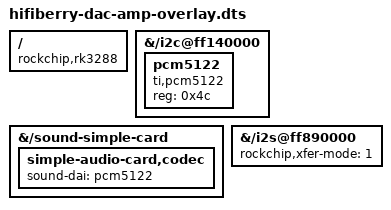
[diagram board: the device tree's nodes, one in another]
/dts-v1/;
/plugin/;

/ {
	compatible = "rockchip,rk3288";

	fragment@0 {
		target-path = "/i2c@ff140000";
		__overlay__ {
			pcm5122: pcm5122 {
				#sound-dai-cells = <0>;
				compatible = "ti,pcm5122";
				reg = <0x4c>;
				status = "okay";
			};
		};	

	};


	fragment@1 {
		target-path ="/sound-simple-card";
		__overlay__ {
			simple-audio-card,codec {
				sound-dai = <&pcm5122>;
			};
		};
	};

	fragment@2 {
		target-path = "/i2s@ff890000";
		__overlay__ {
			rockchip,xfer-mode = <1>;
		};
	};

};
